# PIC32CK1012SG01048 device description
Architecture: CORTEX-M33; Family: PIC32CK; Series: PIC32CKSG01
Registers are 32-bit, read-write, reset 0x0 unless marked. A register's access mark holds for its fields unless they carry their own. Offsets are from the block's base; [hi:lo] are bit positions; {n}, {i} and the like mark numbered series; 'fields as' and 'values as' point back to an identical list.

## NVIC — Nested Vectored Interrupt Controller
Instances: NVIC 0xE000E100, NVIC_NS 0xE002E100
{0x0+4i} ISER[{i}] (i=0..4) reset not defined — Interrupt Set Enable Register n
  [31:0] SETENA — Set enable
{0x80+4i} ICER[{i}] (i=0..4) reset not defined — Interrupt Clear Enable Register n
  [31:0] CLRENA — Clear enable
{0x100+4i} ISPR[{i}] (i=0..4) reset not defined — Interrupt Set Pending Register n
  [31:0] SETPEND — Set pending
{0x180+4i} ICPR[{i}] (i=0..4) reset not defined — Interrupt Clear Pending Register n
  [31:0] CLRPEND — Clear pending
{0x200+4i} IABR[{i}] (i=0..4) ro reset not defined — Interrupt Active Bit Register n
  [31:0] ACTIVE — Active state
{0x280+4i} ITNS[{i}] (i=0..4) reset not defined — Interrupt Target Non-secure Register n
  [31:0] ITNS — Interrupt Targets Non-secure
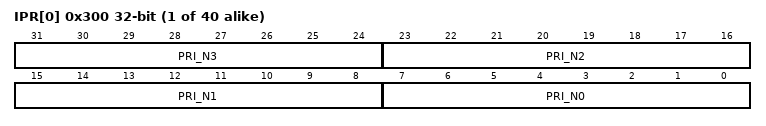
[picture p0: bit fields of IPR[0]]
{0x300+4i} IPR[{i}] (i=0..39) reset not defined — Interrupt Priority Register n
  [8n+7:8n] PRI_N{n} (n=0..3) — Priority of interrupt number 4n+{n}
0xE00 STIR wo reset not defined — Software Triggered Interrupt Register
  [8:0] INTID — Interrupt ID of the interrupt to trigger, in the range 0-479. For example, a value of 0x03 specifies interrupt IRQ3.

## OSC32KCTRL — 32kHz Oscillators Control
Instances: OSC32KCTRL 0x4400E000
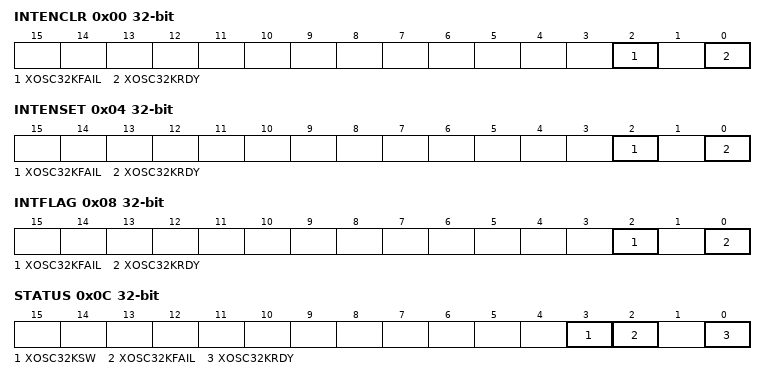
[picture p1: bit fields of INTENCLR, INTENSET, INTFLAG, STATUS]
0x00 INTENCLR (atomic clear) — Interrupt Enable Clear
  [2] XOSC32KFAIL — XOSC32K Clock Failure Detector Interrupt Enable
  [0] XOSC32KRDY — XOSC32K Ready Interrupt Enable
0x04 INTENSET (atomic set) — Interrupt Enable Set
  fields as INTENCLR
0x08 INTFLAG (atomic clear) — Interrupt Flag Status and Clear
  [2] XOSC32KFAIL — XOSC32K Clock Failure Detector
  [0] XOSC32KRDY — XOSC32K Ready
0x0C STATUS ro — Power and Clocks Status
  [3] XOSC32KSW — XOSC32K Clock switch
  [2] XOSC32KFAIL — XOSC32K Clock Failure Detector
  [0] XOSC32KRDY — XOSC32K Ready
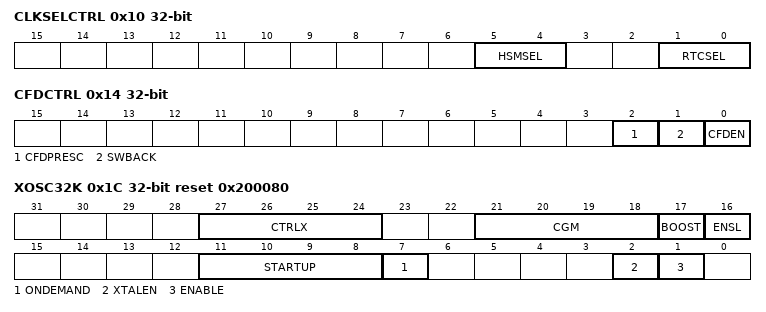
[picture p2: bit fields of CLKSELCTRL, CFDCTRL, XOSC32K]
0x10 CLKSELCTRL — Clock Selection Control
  [5:4] HSMSEL — HSM Clock Selection
    0=ULP32K (32.768kHz from 32kHz internal ULP oscillator); 2=XOSC32K (32.768kHz from 32.768kHz external crystal oscillator)
  [1:0] RTCSEL — RTC Clock Selection
    0=ULP32K (32.768kHz from 32kHz internal ULP oscillator); 1=ULP1K (1.024kHz from 32kHz internal ULP oscillator); 2=XOSC32K (32.768kHz from 32.768kHz external crystal oscillator); 3=XOSC1K (1.024kHz from 32.768kHz internal oscillator)
0x14 CFDCTRL — Clock Failure Detector Control
  [2] CFDPRESC — Clock Failure Detector Prescaler
  [1] SWBACK — Clock Switch Back
  [0] CFDEN — Clock Failure Detector Enable
0x18 EVCTRL — Event Control
  [0] CFDEO — Clock Failure Detector Event Output Enable
0x1C XOSC32K reset 0x200080 — 32kHz External Crystal Oscillator (XOSC32K) Control
  [27:24] CTRLX — Extended Control
  [21:18] CGM — Control Gain Mode
    0=The lower Control Gain Mode value; {v}=A higher Control Gain Mode value than CGM{v-1} (v=1..14); 15=The highest Control Gain Mode value
  [17] BOOST — Gain Boost
  [16] ENSL — Enable Servo Loop
  [11:8] STARTUP — Startup Mode
    0=1CYCLE (1 ULP clock cycle); 1=16CYCLES (16 ULP clock cycles); 2=32CYCLES (32 ULP clock cycles); 3=2048CYCLES (2048 ULP clock cycles); 4=4096CYCLES (4096 ULP clock cycles); 5=8192CYCLES (8192 ULP clock cycles); 6=16384CYCLES (16384 ULP clock cycles); 7=32768CYCLES (32768 ULP clock cycles); 8=65536CYCLES (65536 ULP clock cycles); 9=131072CYCLES (131072 ULP clock cycles); 10=262144CYCLES (262144 ULP clock cycles)
  [7] ONDEMAND — On Demand Mode
  [2] XTALEN — Crystal Oscillator Enable
  [1] ENABLE — Oscillator Enable

## PAC — Peripheral Access Controller
Instances: PAC 0x4401C000
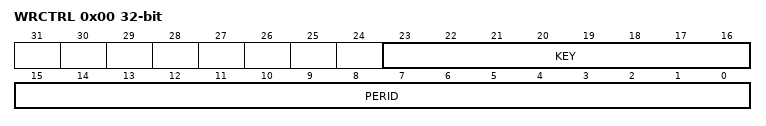
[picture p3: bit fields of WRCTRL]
0x00 WRCTRL — Write control
  [23:16] KEY — Peripheral access control key
    0=OFF (No action); 1=CLR (Clear protection); 2=SET (Set protection); 3=SETLCK (Set and lock protection)
  [15:0] PERID — Peripheral identifier
0x04 EVCTRL 8-bit — Event control
  [0] ERREO — Peripheral acess error event output
0x08 INTENCLR 8-bit (atomic clear) — Interrupt enable clear
  [0] ERR — Peripheral access error interrupt disable
0x09 INTENSET 8-bit (atomic set) — Interrupt enable set
  [0] ERR — Peripheral access error interrupt enable
0x10 INTFLAGAHB (atomic clear) — Bridge interrupt flag status
0x14 INTFLAGA (atomic clear) — Peripheral interrupt flag status - Bridge A
0x18 INTFLAGB (atomic clear) — Peripheral interrupt flag status - Bridge B
0x1C INTFLAGC (atomic clear) — Peripheral interrupt flag status - Bridge C
0x20 INTFLAGD (atomic clear) — Peripheral interrupt flag status - Bridge D
0x34 STATUSA ro reset 0xF0000 — Peripheral write protection status - Bridge A
0x38 STATUSB ro — Peripheral write protection status - Bridge B
0x3C STATUSC ro — Peripheral write protection status - Bridge C
0x40 STATUSD ro — Peripheral write protection status - Bridge D
0x54 NONSECA ro — Peripheral Non-Secure Status - Bridge A
0x58 NONSECB ro — Peripheral Non-Secure Status - Bridge B
0x5C NONSECC ro — Peripheral Non-Secure Status - Bridge C
0x60 NONSECD ro — Peripheral Non-Secure Status - Bridge D
0x74 SECLOCKA ro — Peripheral Security Lock Status - Bridge A
0x78 SECLOCKB ro — Peripheral Security Lock Status - Bridge B
0x7C SECLOCKC ro — Peripheral Security Lock Status - Bridge C
0x80 SECLOCKD ro — Peripheral Security Lock Status - Bridge D
